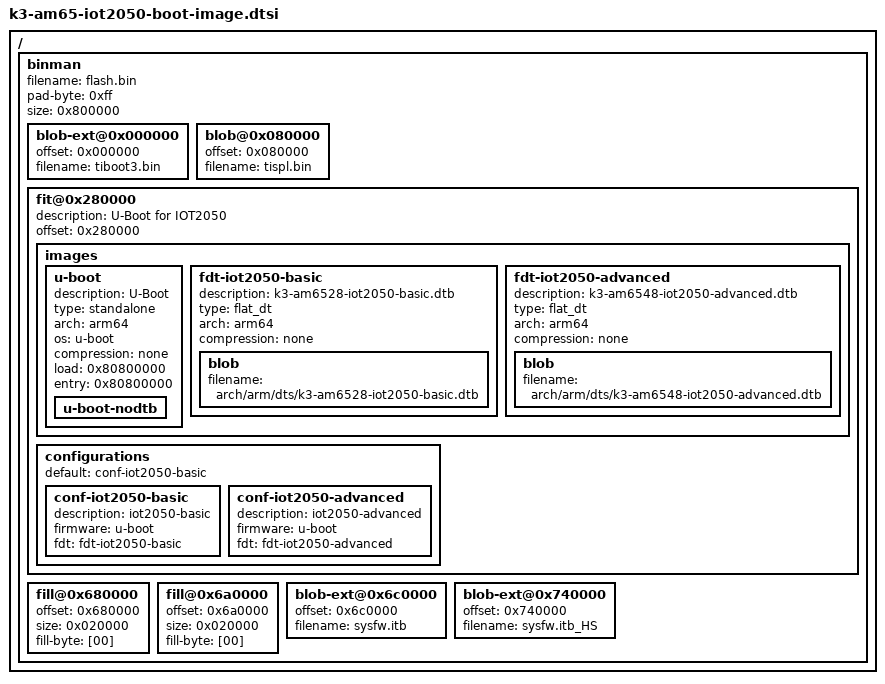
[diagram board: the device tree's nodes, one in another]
// SPDX-License-Identifier: GPL-2.0
/*
 * Copyright (c) Siemens AG, 2020-2021
 *
 * Authors:
 *   Jan Kiszka <jan.kiszk@siemens.com>
 */

#include <config.h>

/ {
	binman {
		filename = "flash.bin";
		pad-byte = <0xff>;
		size = <0x800000>;

		blob-ext@0x000000 {
			offset = <0x000000>;
			filename = "tiboot3.bin";
		};

		blob@0x080000 {
			offset = <0x080000>;
			filename = "tispl.bin";
		};

		fit@0x280000 {
			description = "U-Boot for IOT2050";
			offset = <0x280000>;
			images {
				u-boot {
					description = "U-Boot";
					type = "standalone";
					arch = "arm64";
					os = "u-boot";
					compression = "none";
					load = <0x80800000>;
					entry = <0x80800000>;
					u-boot-nodtb {
					};
				};

				fdt-iot2050-basic {
					description = "k3-am6528-iot2050-basic.dtb";
					type = "flat_dt";
					arch = "arm64";
					compression = "none";
					blob {
						filename = "arch/arm/dts/k3-am6528-iot2050-basic.dtb";
					};
				};

				fdt-iot2050-advanced {
					description = "k3-am6548-iot2050-advanced.dtb";
					type = "flat_dt";
					arch = "arm64";
					compression = "none";
					blob {
						filename = "arch/arm/dts/k3-am6548-iot2050-advanced.dtb";
					};
				};
			};

			configurations {
				default = "conf-iot2050-basic";

				conf-iot2050-basic {
					description = "iot2050-basic";
					firmware = "u-boot";
					fdt = "fdt-iot2050-basic";
				};

				conf-iot2050-advanced {
					description = "iot2050-advanced";
					firmware = "u-boot";
					fdt = "fdt-iot2050-advanced";
				};
			};
		};

		/* primary env */
		fill@0x680000 {
			offset = <0x680000>;
			size   = <0x020000>;
			fill-byte = [00];
		};
		/* secondary env */
		fill@0x6a0000 {
			offset = <0x6a0000>;
			size   = <0x020000>;
			fill-byte = [00];
		};

		/* Sysfw Basic */
		blob-ext@0x6c0000 {
			offset = <0x6c0000>;
			filename = "sysfw.itb";
		};
		/* Sysfw Advanced */
		blob-ext@0x740000 {
			offset = <0x740000>;
			filename = "sysfw.itb_HS";
		};
	};
};
